# MKE16Z4 register map
Vendor: nxp.com; File version: 1.0
CPU: CM0PLUS r0p0, little endian, no MPU, no FPU, VTOR, 2 interrupt priority bits
Registers are 32-bit, read-write, reset 0x0 unless marked. A register's access mark holds for its fields unless they carry their own. Offsets are from the block's base; [hi:lo] are bit positions; {n}, {i} and the like mark numbered series; 'fields as' and 'values as' point back to an identical list.

## EWM — External Watchdog Monitor
Base 0x40061000; register names take the prefix EWM_
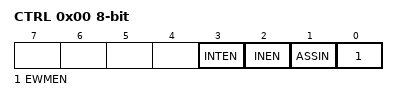
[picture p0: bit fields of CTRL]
0x00 CTRL 8-bit — Control Register
  [3] INTEN — Interrupt Enable.
  [2] INEN — Input Enable.
  [1] ASSIN — EWM_in's Assertion State Select.
  [0] EWMEN — EWM enable.
0x01 SERV 8-bit — Service Register
  [7:0] SERVICE — The EWM refresh mechanism requires the CPU to write two values to the SERV register: a first data byte of 0xB4, followed by a second data byte of 0x2C
0x02 CMPL 8-bit — Compare Low Register
  [7:0] COMPAREL — To prevent runaway code from changing this field, software should write to this field after a CPU reset even if the (default) minimum refresh time is required
0x03 CMPH 8-bit reset 0xFF — Compare High Register
  [7:0] COMPAREH — To prevent runaway code from changing this field, software should write to this field after a CPU reset even if the (default) maximum refresh time is required
0x05 CLKPRESCALER 8-bit — Clock Prescaler Register
  [7:0] CLK_DIV — Selected low power clock source for running the EWM counter can be prescaled as below

## TRGMUX0 — Trigger MUX Control
Base 0x40062000
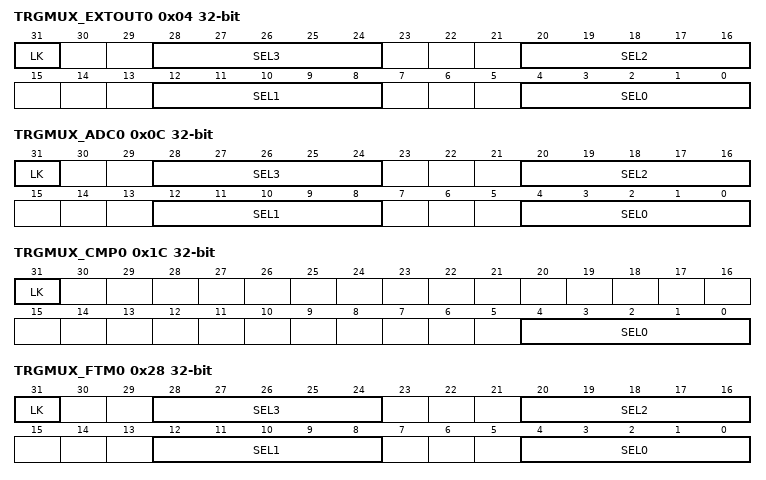
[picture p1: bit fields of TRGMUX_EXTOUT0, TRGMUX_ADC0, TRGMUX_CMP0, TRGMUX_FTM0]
0x04 TRGMUX_EXTOUT0
  [31] LK ro — TRGMUX register lock.
    0=UNLOCKED (Register can be written.); 1=LOCKED (Register cannot be written until the next system Reset.)
  [8n+4:8n] SEL{n} (n=0..3) — Trigger MUX Input {n} Source Select
0x0C TRGMUX_ADC0
  fields as TRGMUX_EXTOUT0
0x1C TRGMUX_CMP0
  [31] LK ro — TRGMUX register lock.
    values as TRGMUX_EXTOUT0.LK
  [4:0] SEL0 — Trigger MUX Input 0 Source Select
0x28 TRGMUX_FTM0
  fields as TRGMUX_EXTOUT0
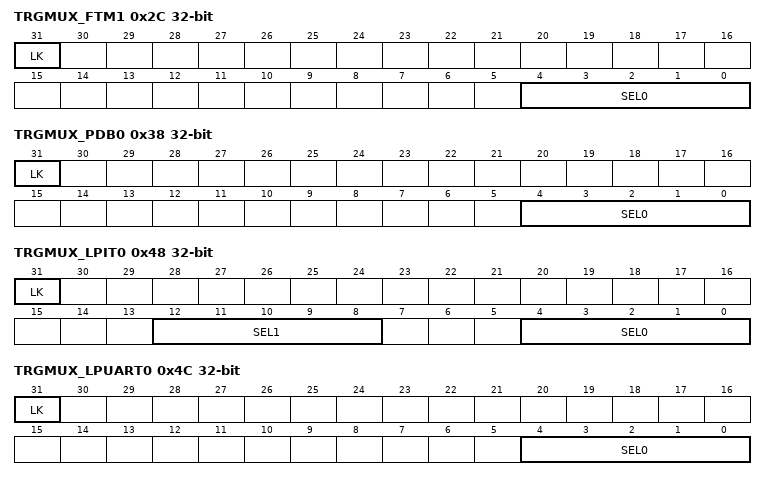
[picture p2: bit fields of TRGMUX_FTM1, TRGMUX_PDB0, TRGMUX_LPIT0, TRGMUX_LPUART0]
0x2C TRGMUX_FTM1
  fields as TRGMUX_CMP0
0x38 TRGMUX_PDB0
  fields as TRGMUX_CMP0
0x48 TRGMUX_LPIT0
  [31] LK ro — TRGMUX register lock.
    values as TRGMUX_EXTOUT0.LK
  [12:8] SEL1 — Trigger MUX Input 1 Source Select
  [4:0] SEL0 — Trigger MUX Input 0 Source Select
0x4C TRGMUX_LPUART0
  fields as TRGMUX_CMP0
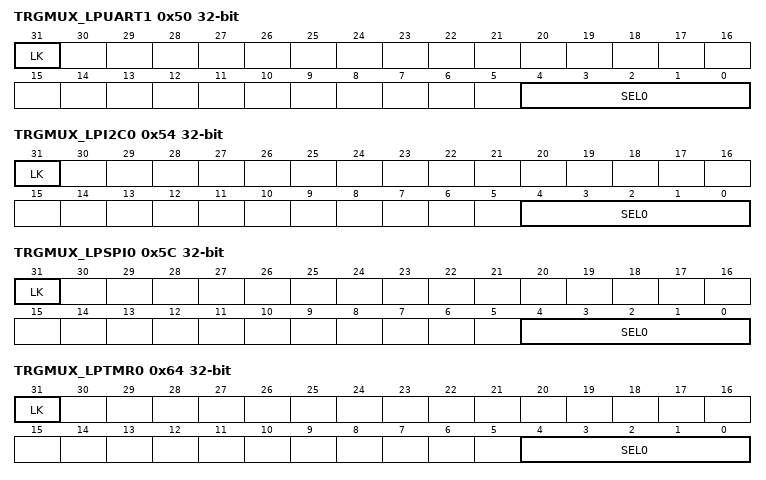
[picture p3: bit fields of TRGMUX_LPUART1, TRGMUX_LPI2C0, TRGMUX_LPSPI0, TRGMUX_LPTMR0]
0x50 TRGMUX_LPUART1
  fields as TRGMUX_CMP0
0x54 TRGMUX_LPI2C0
  fields as TRGMUX_CMP0
0x5C TRGMUX_LPSPI0
  fields as TRGMUX_CMP0
0x64 TRGMUX_LPTMR0
  fields as TRGMUX_CMP0
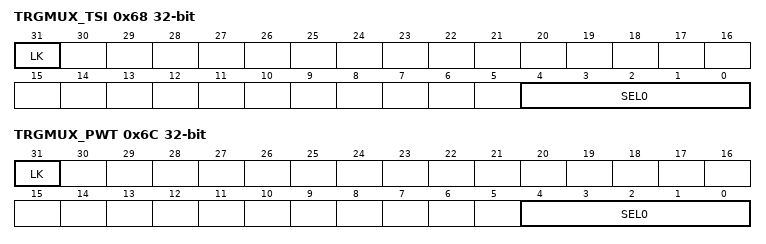
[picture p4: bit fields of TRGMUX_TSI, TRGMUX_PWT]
0x68 TRGMUX_TSI
  fields as TRGMUX_CMP0
0x6C TRGMUX_PWT
  fields as TRGMUX_CMP0

## TRGMUX1 — Trigger MUX Control
Base 0x40063000
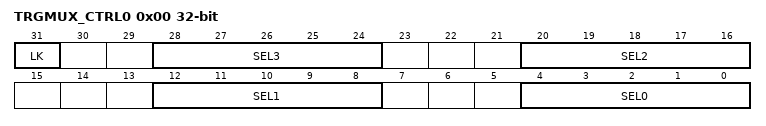
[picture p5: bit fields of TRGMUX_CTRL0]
0x00 TRGMUX_CTRL0
  [31] LK ro — TRGMUX register lock.
    0=UNLOCKED (Register can be written.); 1=LOCKED (Register cannot be written until the next system Reset.)
  [8n+4:8n] SEL{n} (n=0..3) — Trigger MUX Input {n} Source Select

## PCC
Base 0x40065000
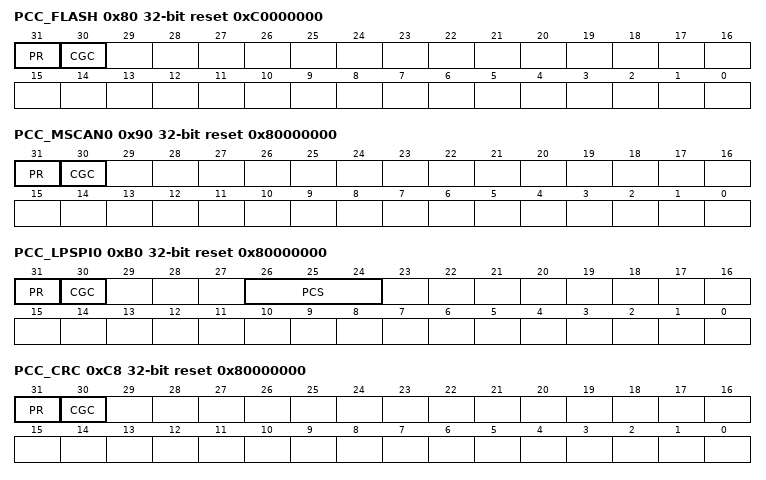
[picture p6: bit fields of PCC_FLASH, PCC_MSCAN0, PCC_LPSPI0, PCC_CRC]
0x80 PCC_FLASH reset 0xC0000000
  [31] PR ro — Present
    0=Peripheral is not present; 1=Peripheral is present
  [30] CGC — Clock Gate Control
    0=Clock disabled; 1=Clock enabled. The current clock selection and divider options are locked.
0x90 PCC_MSCAN0 reset 0x80000000
  fields as PCC_FLASH
0xB0 PCC_LPSPI0 reset 0x80000000
  [31] PR ro — Present
    0=Peripheral is not present; 1=Peripheral is present
  [30] CGC — Clock Gate Control
    values as PCC_FLASH.CGC
  [26:24] PCS — Peripheral Clock Source Select
    0=Clock is off; {v}=Clock option {v} (v=1..7)
0xC8 PCC_CRC reset 0x80000000
  fields as PCC_FLASH
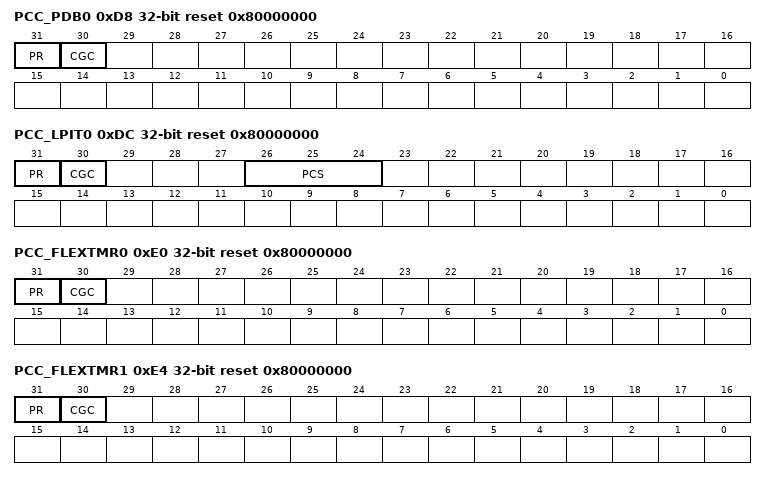
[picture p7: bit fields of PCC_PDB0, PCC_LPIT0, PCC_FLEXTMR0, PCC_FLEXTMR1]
0xD8 PCC_PDB0 reset 0x80000000
  fields as PCC_FLASH
0xDC PCC_LPIT0 reset 0x80000000
  fields as PCC_LPSPI0
0xE0 PCC_FLEXTMR0 reset 0x80000000
  fields as PCC_FLASH
0xE4 PCC_FLEXTMR1 reset 0x80000000
  fields as PCC_FLASH
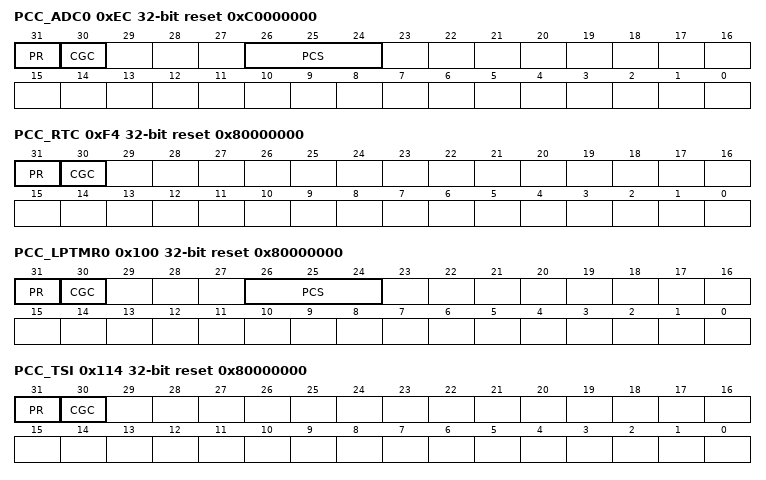
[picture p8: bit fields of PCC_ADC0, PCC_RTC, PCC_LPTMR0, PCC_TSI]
0xEC PCC_ADC0 reset 0xC0000000
  fields as PCC_LPSPI0
0xF4 PCC_RTC reset 0x80000000
  fields as PCC_FLASH
0x100 PCC_LPTMR0 reset 0x80000000
  fields as PCC_LPSPI0
0x114 PCC_TSI reset 0x80000000
  fields as PCC_FLASH
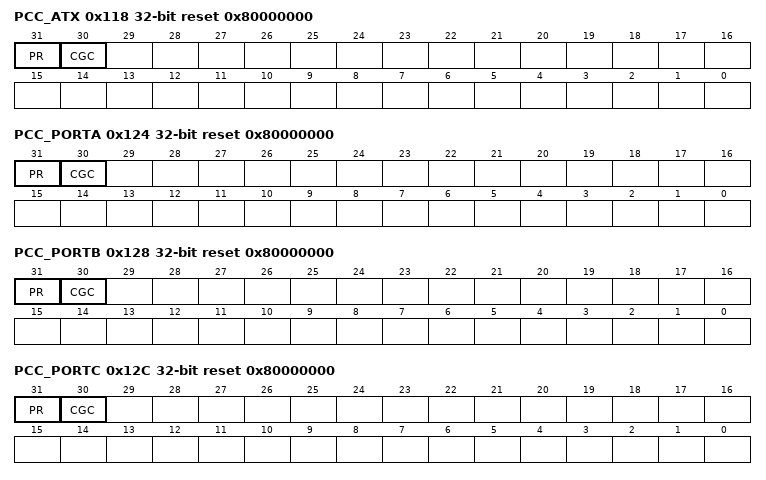
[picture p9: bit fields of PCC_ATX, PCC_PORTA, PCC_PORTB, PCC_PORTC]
0x118 PCC_ATX reset 0x80000000
  fields as PCC_FLASH
0x124 PCC_PORTA reset 0x80000000
  fields as PCC_FLASH
0x128 PCC_PORTB reset 0x80000000
  fields as PCC_FLASH
0x12C PCC_PORTC reset 0x80000000
  fields as PCC_FLASH
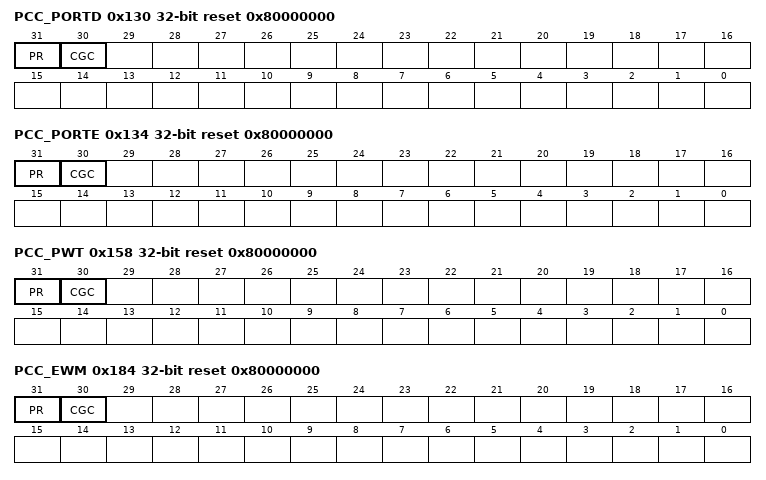
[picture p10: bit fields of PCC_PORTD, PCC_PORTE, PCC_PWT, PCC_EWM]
0x130 PCC_PORTD reset 0x80000000
  fields as PCC_FLASH
0x134 PCC_PORTE reset 0x80000000
  fields as PCC_FLASH
0x158 PCC_PWT reset 0x80000000
  fields as PCC_FLASH
0x184 PCC_EWM reset 0x80000000
  fields as PCC_FLASH
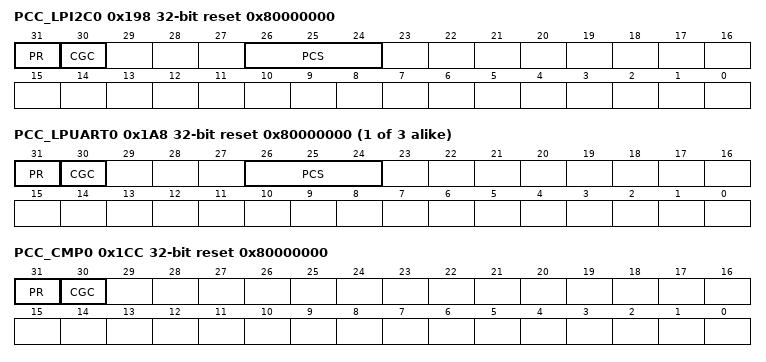
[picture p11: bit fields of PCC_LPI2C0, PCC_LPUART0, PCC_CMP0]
0x198 PCC_LPI2C0 reset 0x80000000
  fields as PCC_LPSPI0
{0x1A8+4i} PCC_LPUART{i} reset 0x80000000 (i=0..2)
  fields as PCC_LPSPI0
0x1CC PCC_CMP0 reset 0x80000000
  fields as PCC_FLASH
